AUTOSAR XML (schema 4-3-0)
package /s1/s2/s3
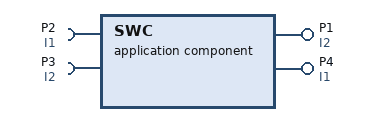
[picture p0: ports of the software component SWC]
  application sw component type SWC
    provide port P1: provided-interface=I2
    require port P2: required-interface=I1
    require port P3: required-interface=I2
    provide port P4: provided-interface=I1
